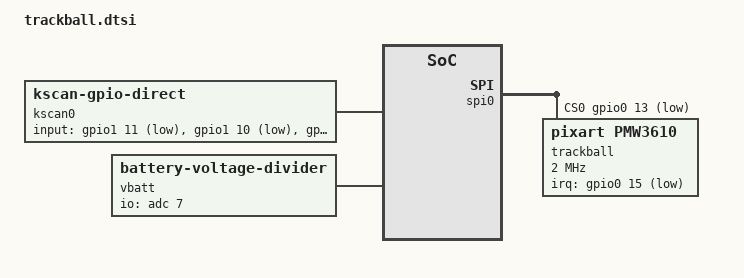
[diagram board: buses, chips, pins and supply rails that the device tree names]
#include <dt-bindings/zmk/matrix_transform.h>
#include <zephyr/dt-bindings/input/input-event-codes.h>
#include "trackball_layout.dtsi"

/ {
    chosen {
        zmk,kscan = &kscan0;
        zmk,physical-layout = &physical_layout;
        zmk,battery = &vbatt;
    };

    kscan0: kscan {
        compatible = "zmk,kscan-gpio-direct";
        wakeup-source;
        input-gpios
        = <&gpio1 11 (GPIO_ACTIVE_LOW | GPIO_PULL_UP)>
        , <&gpio1 10 (GPIO_ACTIVE_LOW | GPIO_PULL_UP)>
        , <&gpio0  3 (GPIO_ACTIVE_LOW | GPIO_PULL_UP)>
        , <&gpio0 28 (GPIO_ACTIVE_LOW | GPIO_PULL_UP)>
        , <&gpio0  0 (GPIO_ACTIVE_LOW | GPIO_PULL_UP)>
        , <&gpio0  1 (GPIO_ACTIVE_LOW | GPIO_PULL_UP)>
        ;
    };

    vbatt: vbatt {
        status = "okay";
        compatible = "zmk,battery-voltage-divider";
        io-channels = <&adc 7>;
        output-ohms = <1564000>;
        full-ohms = <(806000 + 1564000)>;
    };

    trackball_listener: trackball_listener {
        compatible = "zmk,input-listener";
        status = "disabled";
    };

    split_inputs {
        #address-cells = <1>;
        #size-cells = <0>;

        trackball_split: trackball_split@0 {
            compatible = "zmk,input-split";
            reg = <0>;
            status = "disabled";
        };
    };
};

&spi0 {
    status = "disabled";
    cs-gpios = <&gpio0 13 GPIO_ACTIVE_LOW>;

    trackball: trackball@0 {
        status = "disabled";
        compatible = "pixart,pmw3610";
        reg = <0>;
        spi-max-frequency = <2000000>;
        irq-gpios = <&gpio0 15 (GPIO_ACTIVE_LOW | GPIO_PULL_UP)>;
        cpi = <1000>;
        evt-type = <INPUT_EV_REL>;
        x-input-code = <INPUT_REL_X>;
        y-input-code = <INPUT_REL_Y>;

        force-awake;
        /* keep the sensor awake while ZMK activity state is ACTIVE,
           fallback to normal downshift mode after ZMK goes into IDLE / SLEEP mode.
           thus, the sensor would be a `wakeup-source` */
    };
};

&spi0 {
    status = "okay";
};

&trackball {
    status = "okay";
};

&trackball_listener {
    status = "okay";
    device = <&trackball>;
};
